# STM32WB09 register map
File version: 1.0
Registers are 32-bit, read-write, reset 0x0 unless marked. A register's access mark holds for its fields unless they carry their own. Offsets are from the block's base; [hi:lo] are bit positions; {n}, {i} and the like mark numbered series; 'fields as' and 'values as' point back to an identical list.

## RADIO_CTRL
Base 0x60001000
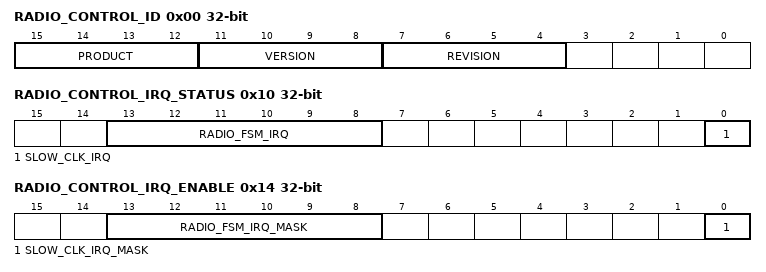
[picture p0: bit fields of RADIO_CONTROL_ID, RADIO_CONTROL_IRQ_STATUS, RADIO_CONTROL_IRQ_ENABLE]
0x00 RADIO_CONTROL_ID
  [15:12] PRODUCT, [11:8] VERSION, [7:4] REVISION
0x04 CLK32COUNT_REG
  [8:0] SLOW_COUNT
0x08 CLK32PERIOD_REG
  [18:0] SLOW_PERIOD
0x0C CLK32FREQUENCY_REG
  [26:0] SLOW_FREQUENCY
0x10 RADIO_CONTROL_IRQ_STATUS
  [13:8] RADIO_FSM_IRQ, [0] SLOW_CLK_IRQ
0x14 RADIO_CONTROL_IRQ_ENABLE
  [13:8] RADIO_FSM_IRQ_MASK, [0] SLOW_CLK_IRQ_MASK

## RRM
Base 0x60001400
0x04 RRM_CTRL
0x10 UDRA_CTRL0
  [0] RELOAD_RDCFGPTR
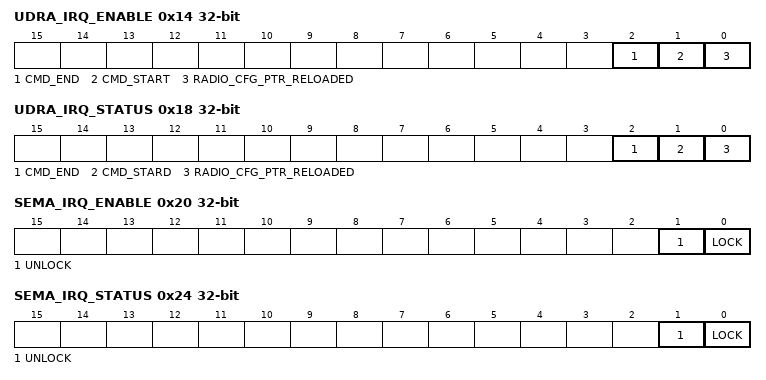
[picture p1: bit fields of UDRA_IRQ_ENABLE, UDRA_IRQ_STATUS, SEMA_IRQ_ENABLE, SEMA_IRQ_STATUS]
0x14 UDRA_IRQ_ENABLE
  [2] CMD_END, [1] CMD_START, [0] RADIO_CFG_PTR_RELOADED
0x18 UDRA_IRQ_STATUS
  [2] CMD_END, [1] CMD_STARD, [0] RADIO_CFG_PTR_RELOADED
0x1C UDRA_RADIO_CFG_PTR
  [31:0] RADIO_CONFIG_ADDRESS
0x20 SEMA_IRQ_ENABLE
  [1] UNLOCK, [0] LOCK
0x24 SEMA_IRQ_STATUS
  [1] UNLOCK, [0] LOCK
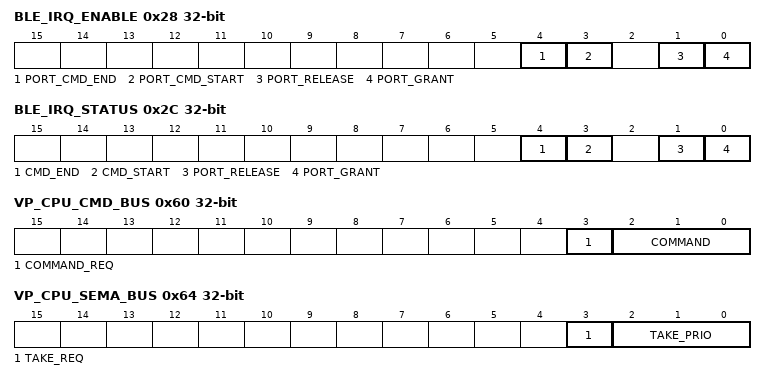
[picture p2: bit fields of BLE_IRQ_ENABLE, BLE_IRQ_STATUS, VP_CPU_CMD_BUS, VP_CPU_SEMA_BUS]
0x28 BLE_IRQ_ENABLE
  [4] PORT_CMD_END, [3] PORT_CMD_START, [1] PORT_RELEASE, [0] PORT_GRANT
0x2C BLE_IRQ_STATUS
  [4] CMD_END, [3] CMD_START, [1] PORT_RELEASE, [0] PORT_GRANT
0x60 VP_CPU_CMD_BUS
  [3] COMMAND_REQ, [2:0] COMMAND
0x64 VP_CPU_SEMA_BUS
  [3] TAKE_REQ, [2:0] TAKE_PRIO
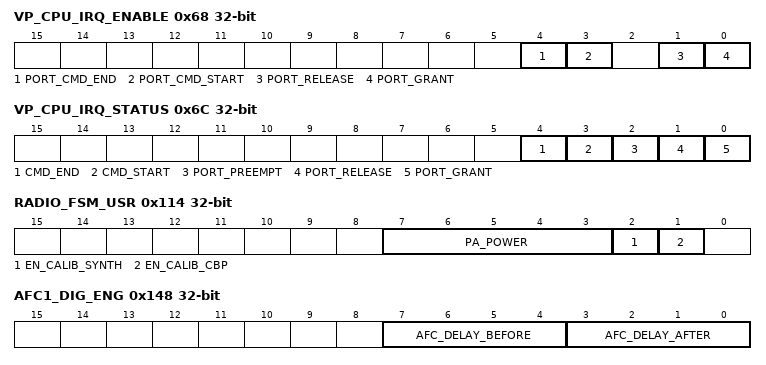
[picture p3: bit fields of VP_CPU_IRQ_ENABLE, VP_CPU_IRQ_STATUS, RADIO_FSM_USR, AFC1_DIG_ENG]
0x68 VP_CPU_IRQ_ENABLE
  fields as BLE_IRQ_ENABLE
0x6C VP_CPU_IRQ_STATUS
  [4] CMD_END, [3] CMD_START, [2] PORT_PREEMPT, [1] PORT_RELEASE, [0] PORT_GRANT
{0x100+4i} AA{i}_DIG_USR (i=0..3)
  [7:0] AA_{8i+7}_{8i}
0x110 DEM_MOD_DIG_USR
  [7:1] CHANNEL_NUM
0x114 RADIO_FSM_USR
  [7:3] PA_POWER, [2] EN_CALIB_SYNTH, [1] EN_CALIB_CBP
0x118 PHYCTRL_DIG_USR
  [2:0] RXTXPHY
0x148 AFC1_DIG_ENG
  [7:4] AFC_DELAY_BEFORE, [3:0] AFC_DELAY_AFTER
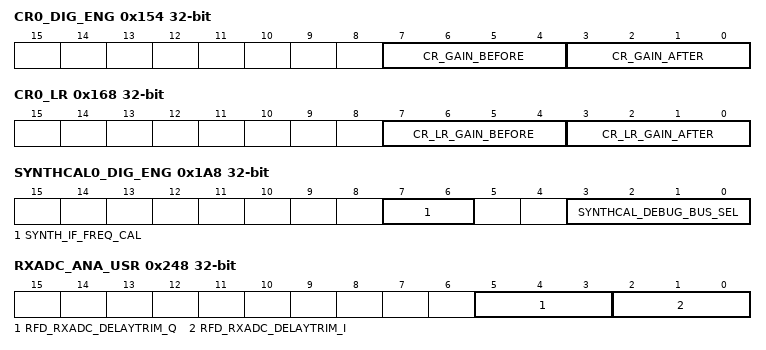
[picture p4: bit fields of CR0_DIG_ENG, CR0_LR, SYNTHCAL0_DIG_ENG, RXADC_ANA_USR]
0x154 CR0_DIG_ENG
  [7:4] CR_GAIN_BEFORE, [3:0] CR_GAIN_AFTER
0x168 CR0_LR
  [7:4] CR_LR_GAIN_BEFORE, [3:0] CR_LR_GAIN_AFTER
0x16C VIT_CONF_DIG_ENG
  [7:0] VIT_CONF
0x184 LR_PD_THR_DIG_ENG
  [7:0] LR_PD_THR
0x188 LR_RSSI_THR_DIG_ENG
  [7:0] LR_RSSI_THR
0x18C LR_AAC_THR_DIG_ENG
  [7:0] LR_AAC_THR
0x1A8 SYNTHCAL0_DIG_ENG
  [7:6] SYNTH_IF_FREQ_CAL, [3:0] SYNTHCAL_DEBUG_BUS_SEL
0x1F0 DTB5_DIG_ENG
{0x234+4i} MOD{i}_DIG_TST (i=0..3)
0x248 RXADC_ANA_USR
  [5:3] RFD_RXADC_DELAYTRIM_Q, [2:0] RFD_RXADC_DELAYTRIM_I
0x254 LDO_ANA_ENG
  [0] RFD_RF_REG_BYPASS
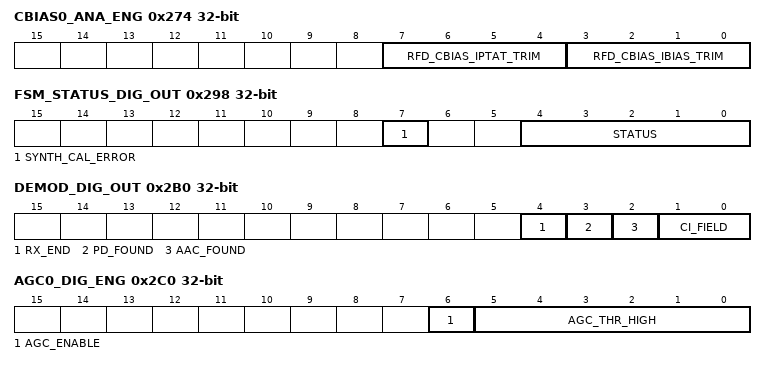
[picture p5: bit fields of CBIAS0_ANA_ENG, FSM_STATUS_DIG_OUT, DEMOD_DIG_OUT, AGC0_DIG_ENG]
0x274 CBIAS0_ANA_ENG
  [7:4] RFD_CBIAS_IPTAT_TRIM, [3:0] RFD_CBIAS_IBIAS_TRIM
0x278 CBIAS1_ANA_ENG
  [3:0] RFD_CBIAS_VBG_TRIM
0x280 SYNTHCAL0_DIG_OUT
  [6:0] VCO_CALAMP_OUT_6_0
0x284 SYNTHCAL1_DIG_OUT
  [3:0] VCO_CALAMP_OUT_10_7
0x288 SYNTHCAL2_DIG_OUT
  [6:0] VCO_CALFREQ_OUT
0x28C SYNTHCAL3_DIG_OUT
  [7:0] SYNTHCAL_DEBUG_BUS
0x290 SYNTHCAL4_DIG_OUT
  [5:0] MOD_REF_DAC_WORD_OUT
0x294 SYNTHCAL5_DIG_OUT
  [3:0] CBP_CALIB_WORD
0x298 FSM_STATUS_DIG_OUT
  [7] SYNTH_CAL_ERROR, [4:0] STATUS
0x2A4 RSSI0_DIG_OUT
  [7:0] RSSI_MEAS_OUT_7_0
0x2A8 RSSI1_DIG_OUT
  [7:0] RSSI_MEAS_OUT_15_8
0x2AC AGC_DIG_OUT
  [3:0] AGC_ATT_OUT
0x2B0 DEMOD_DIG_OUT
  [4] RX_END, [3] PD_FOUND, [2] AAC_FOUND, [1:0] CI_FIELD
0x2C0 AGC0_DIG_ENG
  [6] AGC_ENABLE, [5:0] AGC_THR_HIGH
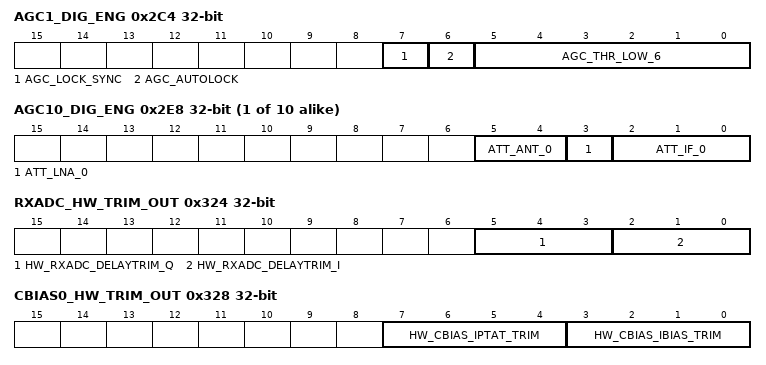
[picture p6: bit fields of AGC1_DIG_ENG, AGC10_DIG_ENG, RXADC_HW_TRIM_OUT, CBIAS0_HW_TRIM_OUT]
0x2C4 AGC1_DIG_ENG
  [7] AGC_LOCK_SYNC, [6] AGC_AUTOLOCK, [5:0] AGC_THR_LOW_6
{0x2C0+4i} AGC{i}_DIG_ENG (i=10..19)
  [5:4] ATT_ANT_{i-10}, [3] ATT_LNA_{i-10}, [2:0] ATT_IF_{i-10}
0x324 RXADC_HW_TRIM_OUT
  [5:3] HW_RXADC_DELAYTRIM_Q, [2:0] HW_RXADC_DELAYTRIM_I
0x328 CBIAS0_HW_TRIM_OUT
  [7:4] HW_CBIAS_IPTAT_TRIM, [3:0] HW_CBIAS_IBIAS_TRIM
0x330 AGC_HW_TRIM_OUT
  [3:1] HW_AGC_ANTENNAE_TRIM
{0x340+4i} ANTSW_DIG{i}_USR (i=0..3)

## WAKEUP
Base 0x60001800
0x08 WAKEUP_OFFSET0
  [7:0] WAKEUP_OFFSET
0x0C WAKEUP_OFFSET1
  [7:0] WAKEUP_OFFSET
0x10 ABSOLUTE_TIME
0x14 MINIMUM_PERIOD_LENGTH
  [13:4] LENGTH
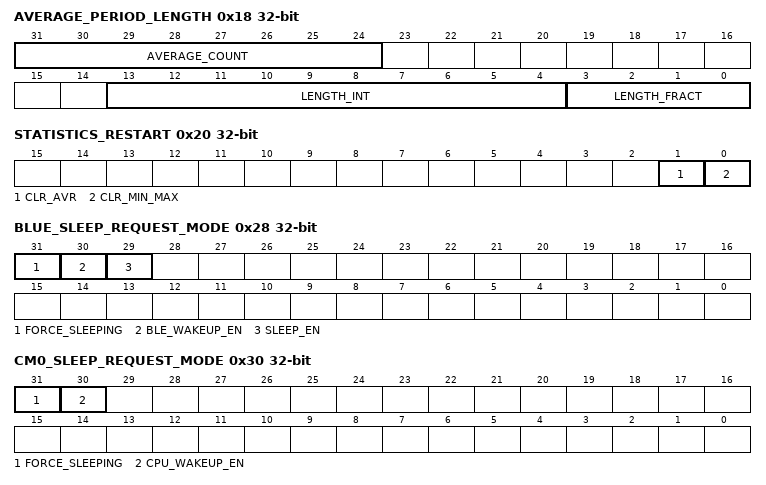
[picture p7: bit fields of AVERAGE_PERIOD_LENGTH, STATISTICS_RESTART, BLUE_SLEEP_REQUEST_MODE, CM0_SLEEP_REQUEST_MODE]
0x18 AVERAGE_PERIOD_LENGTH
  [31:24] AVERAGE_COUNT, [13:4] LENGTH_INT, [3:0] LENGTH_FRACT
0x1C MAXIMUM_PERIOD_LENGTH
  [13:4] LENGTH
0x20 STATISTICS_RESTART
  [1] CLR_AVR, [0] CLR_MIN_MAX
0x24 BLUE_WAKEUP_TIME
  [31:0] WAKEUP_TIME
0x28 BLUE_SLEEP_REQUEST_MODE
  [31] FORCE_SLEEPING, [30] BLE_WAKEUP_EN, [29] SLEEP_EN
0x2C CM0_WAKEUP_TIME
  [31:4] WAKEUP_TIME
0x30 CM0_SLEEP_REQUEST_MODE
  [31] FORCE_SLEEPING, [30] CPU_WAKEUP_EN
0x40 WAKEUP_BLE_IRQ_ENABLE
  [0] WAKEUP_IT
0x44 WAKEUP_BLE_IRQ_STATUS
  [0] WAKEUP_IT
0x48 WAKEUP_CM0_IRQ_ENABLE
  [0] WAKEUP_IT
0x4C WAKEUP_CM0_IRQ_STATUS
  [0] WAKEUP_IT
